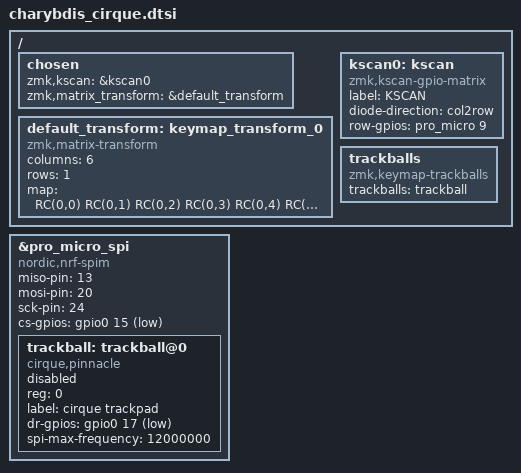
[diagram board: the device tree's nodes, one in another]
#include <dt-bindings/zmk/matrix_transform.h>

/ {
    chosen {
        zmk,kscan = &kscan0;
        zmk,matrix_transform = &default_transform;
    };

    default_transform: keymap_transform_0 {
        compatible = "zmk,matrix-transform";
		columns = <6>;
		rows = <1>;

		map = <
RC(0,0) RC(0,1) RC(0,2) RC(0,3) RC(0,4) RC(0,5) 
		>;
    };

   kscan0: kscan {        
		compatible = "zmk,kscan-gpio-matrix";
		label = "KSCAN";

		diode-direction = "col2row";
		       row-gpios= <&pro_micro 9 (GPIO_ACTIVE_HIGH | GPIO_PULL_DOWN)> // D4
				;
	};

/* Configure trackballs (either split can have the trackball) */
    trackballs {
		compatible = "zmk,keymap-trackballs";
		trackballs = <&trackball>;
	};
};

&pro_micro_spi {
    compatible = "nordic,nrf-spim";
    status = "okay";
    miso-pin = <13>; // P0.13
    mosi-pin = <20>; // P0.20
    sck-pin = <24>; // P0.24
    cs-gpios = <&gpio0 15 GPIO_ACTIVE_LOW>; // P0.15

    trackball: trackball@0 {
        status = "disabled";
        compatible = "cirque,pinnacle";
        reg = <0>;
        label = "cirque trackpad";
	dr-gpios = <&gpio0 17 GPIO_ACTIVE_LOW>;// P0.17
        spi-max-frequency = <12000000>;
        /* sleep; */
    };
};
